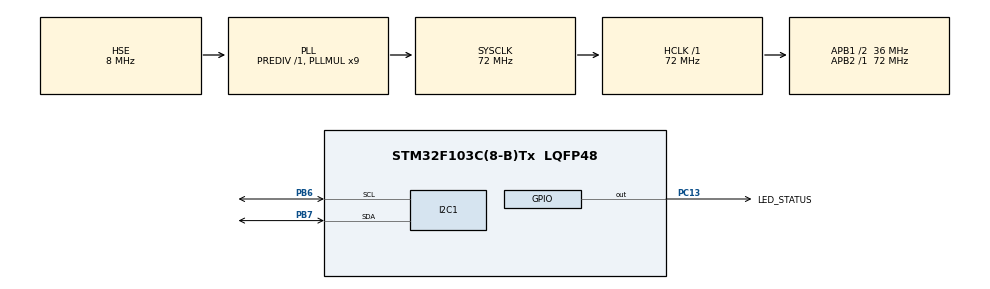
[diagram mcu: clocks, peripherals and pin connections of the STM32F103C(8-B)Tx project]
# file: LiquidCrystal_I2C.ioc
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Dma.MEMTOMEM.0.Direction=DMA_MEMORY_TO_MEMORY
Dma.MEMTOMEM.0.Instance=DMA1_Channel1
Dma.MEMTOMEM.0.MemDataAlignment=DMA_MDATAALIGN_BYTE
Dma.MEMTOMEM.0.MemInc=DMA_MINC_ENABLE
Dma.MEMTOMEM.0.Mode=DMA_NORMAL
Dma.MEMTOMEM.0.PeriphDataAlignment=DMA_PDATAALIGN_BYTE
Dma.MEMTOMEM.0.PeriphInc=DMA_PINC_ENABLE
Dma.MEMTOMEM.0.Priority=DMA_PRIORITY_LOW
Dma.Request0=MEMTOMEM
Mcu.Family=STM32F1
Mcu.Name=STM32F103C(8-B)Tx
Mcu.Package=LQFP48
NVIC.PriorityGroup=NVIC_PRIORITYGROUP_4
NVIC.TIM4_IRQn=true\:0\:0\:false\:false\:true
PA13.Mode=Serial_Wire
PA13.Signal=SYS_JTMS-SWDIO
PA14.Mode=Serial_Wire
PA14.Signal=SYS_JTCK-SWCLK
PB6.Mode=I2C
PB6.Signal=I2C1_SCL
PB7.Mode=I2C
PB7.Signal=I2C1_SDA
PC13-TAMPER-RTC.GPIO_Label=LED_STATUS
PC13-TAMPER-RTC.Signal=GPIO_Output
PD0-OSC_IN.Mode=HSE-External-Oscillator
PD0-OSC_IN.Signal=RCC_OSC_IN
PD1-OSC_OUT.Mode=HSE-External-Oscillator
PD1-OSC_OUT.Signal=RCC_OSC_OUT
ProjectManager.HeapSize=0x200
ProjectManager.StackSize=0x400
ProjectManager.TargetToolchain=Makefile
RCC.ADCPresc=RCC_ADCPCLK2_DIV6
RCC.AHBFreq_Value=72000000
RCC.APB1CLKDivider=RCC_HCLK_DIV2
RCC.APB1Freq_Value=36000000
RCC.APB1TimFreq_Value=72000000
RCC.APB2Freq_Value=72000000
RCC.APB2TimFreq_Value=72000000
RCC.HCLKFreq_Value=72000000
RCC.PLLMUL=RCC_PLL_MUL9
RCC.PLLSourceVirtual=RCC_PLLSOURCE_HSE
RCC.SYSCLKFreq_VALUE=72000000
RCC.SYSCLKSource=RCC_SYSCLKSOURCE_PLLCLK
RCC.USBFreq_Value=72000000
TIM4.AutoReloadPreload=TIM_AUTORELOAD_PRELOAD_ENABLE
TIM4.ClockDivision=TIM_CLOCKDIVISION_DIV1
TIM4.Period=50000-1
TIM4.Prescaler=128-1
TIM4.TIM_MasterOutputTrigger=TIM_TRGO_UPDATE
TIM4.TIM_MasterSlaveMode=TIM_MASTERSLAVEMODE_DISABLE
VP_TIM4_VS_ClockSourceINT.Mode=Internal
board=LiquidCrystal_I2C

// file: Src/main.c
/**
  ******************************************************************************
  * File Name          : main.c
  * Description        : Main program body
  ******************************************************************************
  ** This notice applies to any and all portions of this file
  * that are not between comment pairs USER CODE BEGIN and
  * USER CODE END. Other portions of this file, whether
  * inserted by the user or by software development tools
  * are owned by their respective copyright owners.
  *
  * COPYRIGHT(c) 2018 STMicroelectronics
  *
  * Redistribution and use in source and binary forms, with or without modification,
  * are permitted provided that the following conditions are met:
  *   1. Redistributions of source code must retain the above copyright notice,
  *      this list of conditions and the following disclaimer.
  *   2. Redistributions in binary form must reproduce the above copyright notice,
  *      this list of conditions and the following disclaimer in the documentation
  *      and/or other materials provided with the distribution.
  *   3. Neither the name of STMicroelectronics nor the names of its contributors
  *      may be used to endorse or promote products derived from this software
  *      without specific prior written permission.
  *
  * THIS SOFTWARE IS PROVIDED BY THE COPYRIGHT HOLDERS AND CONTRIBUTORS "AS IS"
  * AND ANY EXPRESS OR IMPLIED WARRANTIES, INCLUDING, BUT NOT LIMITED TO, THE
  * IMPLIED WARRANTIES OF MERCHANTABILITY AND FITNESS FOR A PARTICULAR PURPOSE ARE
  * DISCLAIMED. IN NO EVENT SHALL THE COPYRIGHT HOLDER OR CONTRIBUTORS BE LIABLE
  * FOR ANY DIRECT, INDIRECT, INCIDENTAL, SPECIAL, EXEMPLARY, OR CONSEQUENTIAL
  * DAMAGES (INCLUDING, BUT NOT LIMITED TO, PROCUREMENT OF SUBSTITUTE GOODS OR
  * SERVICES; LOSS OF USE, DATA, OR PROFITS; OR BUSINESS INTERRUPTION) HOWEVER
  * CAUSED AND ON ANY THEORY OF LIABILITY, WHETHER IN CONTRACT, STRICT LIABILITY,
  * OR TORT (INCLUDING NEGLIGENCE OR OTHERWISE) ARISING IN ANY WAY OUT OF THE USE
  * OF THIS SOFTWARE, EVEN IF ADVISED OF THE POSSIBILITY OF SUCH DAMAGE.
  *
  ******************************************************************************
  */
#include "main.h"
#include "stm32f1xx_hal.h"
#include "dma.h"
#include "i2c.h"
#include "tim.h"
#include "gpio.h"

/* USER CODE BEGIN Includes */
#include "SetSysClockTo128.h"
#include "LiquidCrystal_I2C.h"
/* USER CODE END Includes */

/* USER CODE BEGIN PV */
/* Private variables ---------------------------------------------------------*/

uint32_t clk_counter=0;
char str[20];
/* USER CODE END PV */

void SystemClock_Config(void);

/* USER CODE BEGIN PFP */
/* Private function prototypes -----------------------------------------------*/

/* USER CODE END PFP */

/* USER CODE BEGIN 0 */
uint8_t i2c_modul = 0x3f; // address  i2c_module
void lcd_start(void)
{
  LiquidCrystal_I2C_Init(&hi2c1, i2c_modul, 16, 2, LCD_5x8DOTS);
  LiquidCrystal_I2C_SetBacklight(1);
  //LiquidCrystal_I2C_Cursor();
  //LiquidCrystal_I2C_Blink();

  uint8_t fright[8] = {
    0x1F,//11111
    0x1E,//11110
    0x1F,//11111
    0x10,//10000
    0x10,//10000
    0x10,//10000
    0x10,//10000
    0x00
  };

  uint8_t fleft[8] = {
    0x1F,//11111
    0x0F,//01111
    0x1F,//11111
    0x01,//00001
    0x01,//00001
    0x01,//00001
    0x01,//00001
    0x00
  };

  LiquidCrystal_I2C_CreateChar(0, fright);
  LiquidCrystal_I2C_CreateChar(1, fleft);

  LiquidCrystal_I2C_SetCursor(6,1);
  LiquidCrystal_I2C_PrintString("*STM32*");
  LiquidCrystal_I2C_WriteSymbol(0);
  LiquidCrystal_I2C_WriteSymbolCustomDDRAM(0xC5, 1);
  LiquidCrystal_I2C_SetCursor(0,0);
  HAL_Delay(1000);
  LiquidCrystal_I2C_Clear();
}
/* USER CODE END 0 */

int main(void)
{

  /* MCU Configuration----------------------------------------------------------*/

  /* Reset of all peripherals, Initializes the Flash interface and the Systick. */
  HAL_Init();

  /* Configure the system clock */
  SystemClock_Config();

  /* USER CODE BEGIN SysInit */
  HAL_RCC_DeInit();
  SystemClock_Config128();
  /* USER CODE END SysInit */

  /* Initialize all configured peripherals */
  MX_GPIO_Init();
  MX_DMA_Init();
  MX_I2C1_Init();
  MX_TIM4_Init();

  /* USER CODE BEGIN 2 */
  lcd_start();

  uint32_t frq = HAL_RCC_GetHCLKFreq();
  //HAL_TIM_Base_Start(&htim3);
  //HAL_TIM_Base_Start_IT(&htim3);
  HAL_TIM_Base_Start(&htim4);
  HAL_TIM_Base_Start_IT(&htim4);
  /* USER CODE END 2 */

  /* Infinite loop */
  /* USER CODE BEGIN WHILE */
  while (1)
  {
    HAL_Delay(300);

    sprintf(str,"%u",clk_counter);//quantity of steps for the period
    LiquidCrystal_I2C_SetCursor(0, 0);
    LiquidCrystal_I2C_PrintString(str);

    sprintf(str,"%u",frq);//quantity of steps for the period
    LiquidCrystal_I2C_SetCursor(7, 0);
    LiquidCrystal_I2C_PrintString(str);

    sprintf(str,"%u",(clk_counter*1000)/(frq/1000));//period time in microseconds
    LiquidCrystal_I2C_SetCursor(0, 1);
    LiquidCrystal_I2C_PrintString(str);

    sprintf(str,"%u",frq/(clk_counter*2));//frequency in hertz
    LiquidCrystal_I2C_SetCursor(8, 1);
    LiquidCrystal_I2C_PrintString(str);

    HAL_Delay(1000);
  /* USER CODE END WHILE */

  }

}

/** System Clock Configuration
*/
void SystemClock_Config(void)
{

  RCC_OscInitTypeDef RCC_OscInitStruct;
  RCC_ClkInitTypeDef RCC_ClkInitStruct;

    /**Initializes the CPU, AHB and APB busses clocks
    */
  RCC_OscInitStruct.OscillatorType = RCC_OSCILLATORTYPE_HSE;
  RCC_OscInitStruct.HSEState = RCC_HSE_ON;
  RCC_OscInitStruct.HSEPredivValue = RCC_HSE_PREDIV_DIV1;
  RCC_OscInitStruct.HSIState = RCC_HSI_ON;
  RCC_OscInitStruct.PLL.PLLState = RCC_PLL_ON;
  RCC_OscInitStruct.PLL.PLLSource = RCC_PLLSOURCE_HSE;
  RCC_OscInitStruct.PLL.PLLMUL = RCC_PLL_MUL9;
  if (HAL_RCC_OscConfig(&RCC_OscInitStruct) != HAL_OK)
  {
    _Error_Handler(__FILE__, __LINE__);
  }

    /**Initializes the CPU, AHB and APB busses clocks
    */
  RCC_ClkInitStruct.ClockType = RCC_CLOCKTYPE_HCLK|RCC_CLOCKTYPE_SYSCLK
                              |RCC_CLOCKTYPE_PCLK1|RCC_CLOCKTYPE_PCLK2;
  RCC_ClkInitStruct.SYSCLKSource = RCC_SYSCLKSOURCE_PLLCLK;
  RCC_ClkInitStruct.AHBCLKDivider = RCC_SYSCLK_DIV1;
  RCC_ClkInitStruct.APB1CLKDivider = RCC_HCLK_DIV2;
  RCC_ClkInitStruct.APB2CLKDivider = RCC_HCLK_DIV1;

  if (HAL_RCC_ClockConfig(&RCC_ClkInitStruct, FLASH_LATENCY_2) != HAL_OK)
  {
    _Error_Handler(__FILE__, __LINE__);
  }

    /**Configure the Systick interrupt time
    */
  HAL_SYSTICK_Config(HAL_RCC_GetHCLKFreq()/1000);

    /**Configure the Systick
    */
  HAL_SYSTICK_CLKSourceConfig(SYSTICK_CLKSOURCE_HCLK);

  /* SysTick_IRQn interrupt configuration */
  HAL_NVIC_SetPriority(SysTick_IRQn, 0, 0);
}

void _Error_Handler(char * file, int line)
{
  while(1)
  {
  }
}

/************************ (C) COPYRIGHT STMicroelectronics *****END OF FILE****/
